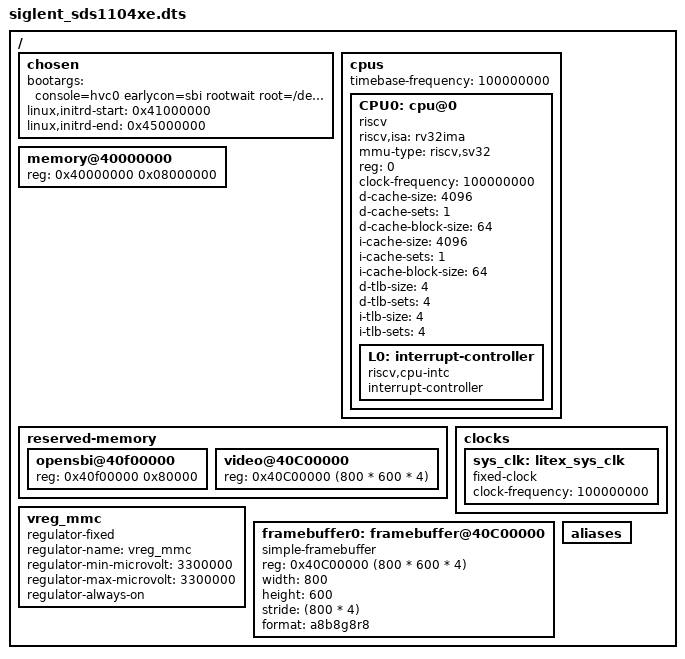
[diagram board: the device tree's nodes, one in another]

/dts-v1/;

/ {
        #address-cells = <1>;
        #size-cells    = <1>;


        chosen {
            bootargs = "console=hvc0 earlycon=sbi rootwait root=/dev/ram0";
            linux,initrd-start = <0x41000000>;
            linux,initrd-end   = <0x45000000>;
        };

        cpus {
            #address-cells = <1>;
            #size-cells    = <0>;
            timebase-frequency = <100000000>;

            CPU0: cpu@0 {
                device_type = "cpu";
                compatible = "riscv";
                riscv,isa = "rv32ima";
                mmu-type = "riscv,sv32";
                reg = <0>;
                clock-frequency = <100000000>;
                status = "okay";
                
                d-cache-size = <4096>;
                d-cache-sets = <1>;
                d-cache-block-size = <64>;

                i-cache-size = <4096>;
                i-cache-sets = <1>;
                i-cache-block-size = <64>;

                
                d-tlb-size = <4>;
                d-tlb-sets = <4>;

                i-tlb-size = <4>;
                i-tlb-sets = <4>;

                L0: interrupt-controller {
                    #interrupt-cells = <0x00000001>;
                    interrupt-controller;
                    compatible = "riscv,cpu-intc";
                };
            };

            
        };

        memory@40000000 {
            device_type = "memory";
            reg = <0x40000000 0x08000000>;
        };

        reserved-memory {
            #address-cells = <1>;
            #size-cells    = <1>;
            ranges;

            opensbi@40f00000 {
                reg = <0x40f00000 0x80000>;
            };
            
            video@40C00000 {
                reg = <0x40C00000 (800 * 600 * 4)>;
            };

        };

        clocks {
            sys_clk: litex_sys_clk {
                #clock-cells = <0>;
                compatible = "fixed-clock";
                clock-frequency = <100000000>;
            };
        };

        vreg_mmc: vreg_mmc {
            compatible = "regulator-fixed";
            regulator-name = "vreg_mmc";
            regulator-min-microvolt = <3300000>;
            regulator-max-microvolt = <3300000>;
            regulator-always-on;
        };


        framebuffer0: framebuffer@40C00000 {
                compatible = "simple-framebuffer";
                reg = <0x40C00000 (800 * 600 * 4)>;
                width = <800>;
                height = <600>;
                stride = <(800 * 4)>;
                format = "a8b8g8r8";
        };

        aliases {


        };

};
